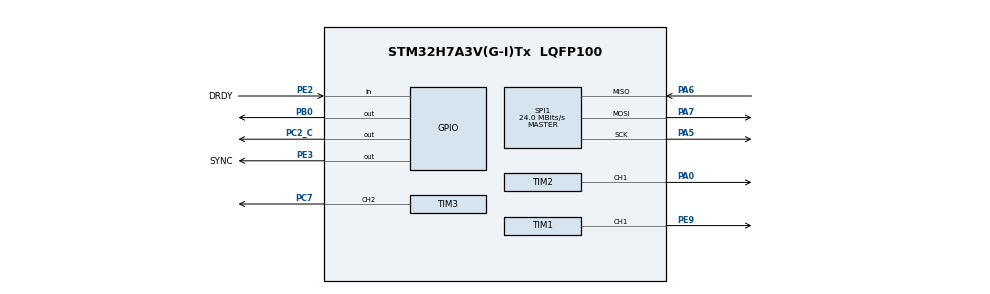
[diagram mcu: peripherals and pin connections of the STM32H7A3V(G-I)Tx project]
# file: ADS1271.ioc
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Mcu.Family=STM32H7
Mcu.Name=STM32H7A3V(G-I)Tx
Mcu.Package=LQFP100
NVIC.PriorityGroup=NVIC_PRIORITYGROUP_4
PA0.Signal=S_TIM2_CH1_ETR
PA5.Mode=Full_Duplex_Master
PA5.Signal=SPI1_SCK
PA6.Mode=Full_Duplex_Master
PA6.Signal=SPI1_MISO
PA7.Mode=Full_Duplex_Master
PA7.Signal=SPI1_MOSI
PB0.Signal=GPIO_Output
PB14.Signal=S_TIM12_CH1
PC2_C.Signal=GPIO_Output
PC7.Signal=S_TIM3_CH2
PE2.GPIO_Label=DRDY
PE2.Signal=GPIO_Input
PE3.GPIO_Label=SYNC
PE3.Signal=GPIO_Output
PE9.Signal=S_TIM1_CH1
ProjectManager.HeapSize=0x200
ProjectManager.StackSize=0x400
ProjectManager.TargetToolchain=STM32CubeIDE
RCC.ADCFreq_Value=96000000
RCC.APB1Freq_Value=140000000
RCC.APB2Freq_Value=140000000
RCC.APB3Freq_Value=140000000
RCC.APB4Freq_Value=140000000
RCC.CDPPRE=RCC_APB3_DIV2
RCC.CDPPRE1=RCC_APB1_DIV2
RCC.CDPPRE2=RCC_APB2_DIV2
RCC.CortexFreq_Value=280000000
RCC.DIVM1=16
RCC.DIVN1=140
RCC.DIVN2=144
RCC.DIVP2=3
RCC.HCLKFreq_Value=280000000
RCC.SPI123CLockSelection=RCC_SPI123CLKSOURCE_PLL2
RCC.SRDPPRE=RCC_APB4_DIV2
RCC.SYSCLKFreq_VALUE=280000000
RCC.SYSCLKSource=RCC_SYSCLKSOURCE_PLLCLK
RCC.USBFreq_Value=280000000
SH.S_TIM12_CH1.0=TIM12_CH1
SH.S_TIM1_CH1.0=TIM1_CH1,PWM Generation1 CH1
SH.S_TIM2_CH1_ETR.0=TIM2_CH1,PWM Generation1 CH1
SH.S_TIM3_CH2.0=TIM3_CH2,PWM Generation2 CH2
SPI1.BaudRatePrescaler=SPI_BAUDRATEPRESCALER_4
SPI1.CalculateBaudRate=24.0 MBits/s
SPI1.DataSize=SPI_DATASIZE_8BIT
SPI1.Direction=SPI_DIRECTION_2LINES
SPI1.Mode=SPI_MODE_MASTER
SPI1.VirtualType=VM_MASTER
TIM1.AutoReloadPreload=TIM_AUTORELOAD_PRELOAD_ENABLE
TIM1.Channel-PWM\ Generation1\ CH1=TIM_CHANNEL_1
TIM1.Period=10
TIM1.Prescaler=1-1
TIM2.AutoReloadPreload=TIM_AUTORELOAD_PRELOAD_ENABLE
TIM2.Channel-PWM\ Generation1\ CH1=TIM_CHANNEL_1
TIM2.Period=6
TIM2.Prescaler=2-1
TIM3.AutoReloadPreload=TIM_AUTORELOAD_PRELOAD_ENABLE
TIM3.Channel-PWM\ Generation2\ CH2=TIM_CHANNEL_2
TIM3.Period=6
TIM3.Prescaler=2-1
VP_TIM1_VS_ClockSourceINT.Mode=Internal
VP_TIM2_VS_ClockSourceINT.Mode=Internal
VP_TIM3_VS_ClockSourceINT.Mode=Internal
board=custom

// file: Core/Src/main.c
/* USER CODE BEGIN Header */
/**
  ******************************************************************************
  * @file           : main.c
  * @brief          : Main program body
  ******************************************************************************
  * @attention
  *
  * Copyright (c) 2024 STMicroelectronics.
  * All rights reserved.
  *
  * This software is licensed under terms that can be found in the LICENSE file
  * in the root directory of this software component.
  * If no LICENSE file comes with this software, it is provided AS-IS.
  *
  ******************************************************************************
  */
/* USER CODE END Header */
#include "main.h"

/* USER CODE BEGIN Includes */
#include "ads1271.h"
/* USER CODE END Includes */

SPI_HandleTypeDef hspi1;

TIM_HandleTypeDef htim1;
TIM_HandleTypeDef htim2;
TIM_HandleTypeDef htim3;

/* USER CODE BEGIN PV */
uint8_t tx_data[3] = {0x55};
uint8_t rx_data[3] = {0};
//int count = 0;

/* USER CODE END PV */

void SystemClock_Config(void);
static void MX_GPIO_Init(void);
static void MX_SPI1_Init(void);
static void MX_TIM1_Init(void);
static void MX_TIM3_Init(void);
static void MX_TIM2_Init(void);

int main(void)
{

  /* MCU Configuration--------------------------------------------------------*/

  /* Reset of all peripherals, Initializes the Flash interface and the Systick. */
  HAL_Init();

  /* Configure the system clock */
  SystemClock_Config();

  /* Initialize all configured peripherals */
  MX_GPIO_Init();
  MX_SPI1_Init();
  MX_TIM1_Init();
  MX_TIM3_Init();
  MX_TIM2_Init();
  /* USER CODE BEGIN 2 */
//  HAL_Delay(10000);

  HAL_GPIO_WritePin(GPIOB, GPIO_PIN_0, GPIO_PIN_SET);
TIM2->CCR1 = 3;
HAL_TIM_PWM_Start(&htim2, HAL_TIM_ACTIVE_CHANNEL_1);
//HAL_Delay(1);
//GPIOE->BSRR |= CS1_HIGH;
  /* USER CODE END 2 */

  /* Infinite loop */
  while (1)
  {

    /* USER CODE BEGIN 3 */

HAL_GPIO_WritePin(GPIOC, GPIO_PIN_2, GPIO_PIN_SET);
HAL_GPIO_WritePin(GPIOE, GPIO_PIN_3, GPIO_PIN_SET);
HAL_Delay(10);
HAL_GPIO_WritePin(GPIOC, GPIO_PIN_2, GPIO_PIN_RESET);
HAL_GPIO_WritePin(GPIOE, GPIO_PIN_3, GPIO_PIN_RESET);
HAL_Delay(10);

	 HAL_GPIO_WritePin(GPIOE, GPIO_PIN_3, GPIO_PIN_SET);

//	  SPI_rxtx(tx_data, rx_data, 3);
//	  for(int i = 0; i< 10000;i++);

  }
  /* USER CODE END 3 */
}

void SystemClock_Config(void)
{
  RCC_OscInitTypeDef RCC_OscInitStruct = {0};
  RCC_ClkInitTypeDef RCC_ClkInitStruct = {0};

  /*AXI clock gating */
  RCC->CKGAENR = 0xFFFFFFFF;

  /** Supply configuration update enable
  */
  HAL_PWREx_ConfigSupply(PWR_LDO_SUPPLY);

  /** Configure the main internal regulator output voltage
  */
  __HAL_PWR_VOLTAGESCALING_CONFIG(PWR_REGULATOR_VOLTAGE_SCALE0);

  while(!__HAL_PWR_GET_FLAG(PWR_FLAG_VOSRDY)) {}

  /** Initializes the RCC Oscillators according to the specified parameters
  * in the RCC_OscInitTypeDef structure.
  */
  RCC_OscInitStruct.OscillatorType = RCC_OSCILLATORTYPE_HSI;
  RCC_OscInitStruct.HSIState = RCC_HSI_DIV1;
  RCC_OscInitStruct.HSICalibrationValue = 64;
  RCC_OscInitStruct.PLL.PLLState = RCC_PLL_ON;
  RCC_OscInitStruct.PLL.PLLSource = RCC_PLLSOURCE_HSI;
  RCC_OscInitStruct.PLL.PLLM = 16;
  RCC_OscInitStruct.PLL.PLLN = 140;
  RCC_OscInitStruct.PLL.PLLP = 2;
  RCC_OscInitStruct.PLL.PLLQ = 2;
  RCC_OscInitStruct.PLL.PLLR = 2;
  RCC_OscInitStruct.PLL.PLLRGE = RCC_PLL1VCIRANGE_2;
  RCC_OscInitStruct.PLL.PLLVCOSEL = RCC_PLL1VCOWIDE;
  RCC_OscInitStruct.PLL.PLLFRACN = 0;
  if (HAL_RCC_OscConfig(&RCC_OscInitStruct) != HAL_OK)
  {
    Error_Handler();
  }

  /** Initializes the CPU, AHB and APB buses clocks
  */
  RCC_ClkInitStruct.ClockType = RCC_CLOCKTYPE_HCLK|RCC_CLOCKTYPE_SYSCLK
                              |RCC_CLOCKTYPE_PCLK1|RCC_CLOCKTYPE_PCLK2
                              |RCC_CLOCKTYPE_D3PCLK1|RCC_CLOCKTYPE_D1PCLK1;
  RCC_ClkInitStruct.SYSCLKSource = RCC_SYSCLKSOURCE_PLLCLK;
  RCC_ClkInitStruct.SYSCLKDivider = RCC_SYSCLK_DIV1;
  RCC_ClkInitStruct.AHBCLKDivider = RCC_HCLK_DIV1;
  RCC_ClkInitStruct.APB3CLKDivider = RCC_APB3_DIV2;
  RCC_ClkInitStruct.APB1CLKDivider = RCC_APB1_DIV2;
  RCC_ClkInitStruct.APB2CLKDivider = RCC_APB2_DIV2;
  RCC_ClkInitStruct.APB4CLKDivider = RCC_APB4_DIV2;

  if (HAL_RCC_ClockConfig(&RCC_ClkInitStruct, FLASH_LATENCY_6) != HAL_OK)
  {
    Error_Handler();
  }
}

static void MX_SPI1_Init(void)
{

  /* SPI1 parameter configuration*/
  hspi1.Instance = SPI1;
  hspi1.Init.Mode = SPI_MODE_MASTER;
  hspi1.Init.Direction = SPI_DIRECTION_2LINES;
  hspi1.Init.DataSize = SPI_DATASIZE_8BIT;
  hspi1.Init.CLKPolarity = SPI_POLARITY_LOW;
  hspi1.Init.CLKPhase = SPI_PHASE_1EDGE;
  hspi1.Init.NSS = SPI_NSS_SOFT;
  hspi1.Init.BaudRatePrescaler = SPI_BAUDRATEPRESCALER_4;
  hspi1.Init.FirstBit = SPI_FIRSTBIT_MSB;
  hspi1.Init.TIMode = SPI_TIMODE_DISABLE;
  hspi1.Init.CRCCalculation = SPI_CRCCALCULATION_DISABLE;
  hspi1.Init.CRCPolynomial = 0x0;
  hspi1.Init.NSSPMode = SPI_NSS_PULSE_ENABLE;
  hspi1.Init.NSSPolarity = SPI_NSS_POLARITY_LOW;
  hspi1.Init.FifoThreshold = SPI_FIFO_THRESHOLD_01DATA;
  hspi1.Init.TxCRCInitializationPattern = SPI_CRC_INITIALIZATION_ALL_ZERO_PATTERN;
  hspi1.Init.RxCRCInitializationPattern = SPI_CRC_INITIALIZATION_ALL_ZERO_PATTERN;
  hspi1.Init.MasterSSIdleness = SPI_MASTER_SS_IDLENESS_00CYCLE;
  hspi1.Init.MasterInterDataIdleness = SPI_MASTER_INTERDATA_IDLENESS_00CYCLE;
  hspi1.Init.MasterReceiverAutoSusp = SPI_MASTER_RX_AUTOSUSP_DISABLE;
  hspi1.Init.MasterKeepIOState = SPI_MASTER_KEEP_IO_STATE_DISABLE;
  hspi1.Init.IOSwap = SPI_IO_SWAP_DISABLE;
  if (HAL_SPI_Init(&hspi1) != HAL_OK)
  {
    Error_Handler();
  }

}

static void MX_TIM1_Init(void)
{

  TIM_ClockConfigTypeDef sClockSourceConfig = {0};
  TIM_MasterConfigTypeDef sMasterConfig = {0};
  TIM_OC_InitTypeDef sConfigOC = {0};
  TIM_BreakDeadTimeConfigTypeDef sBreakDeadTimeConfig = {0};

  htim1.Instance = TIM1;
  htim1.Init.Prescaler = 1-1;
  htim1.Init.CounterMode = TIM_COUNTERMODE_UP;
  htim1.Init.Period = 10;
  htim1.Init.ClockDivision = TIM_CLOCKDIVISION_DIV1;
  htim1.Init.RepetitionCounter = 0;
  htim1.Init.AutoReloadPreload = TIM_AUTORELOAD_PRELOAD_ENABLE;
  if (HAL_TIM_Base_Init(&htim1) != HAL_OK)
  {
    Error_Handler();
  }
  sClockSourceConfig.ClockSource = TIM_CLOCKSOURCE_INTERNAL;
  if (HAL_TIM_ConfigClockSource(&htim1, &sClockSourceConfig) != HAL_OK)
  {
    Error_Handler();
  }
  if (HAL_TIM_PWM_Init(&htim1) != HAL_OK)
  {
    Error_Handler();
  }
  sMasterConfig.MasterOutputTrigger = TIM_TRGO_RESET;
  sMasterConfig.MasterOutputTrigger2 = TIM_TRGO2_RESET;
  sMasterConfig.MasterSlaveMode = TIM_MASTERSLAVEMODE_DISABLE;
  if (HAL_TIMEx_MasterConfigSynchronization(&htim1, &sMasterConfig) != HAL_OK)
  {
    Error_Handler();
  }
  sConfigOC.OCMode = TIM_OCMODE_PWM1;
  sConfigOC.Pulse = 0;
  sConfigOC.OCPolarity = TIM_OCPOLARITY_HIGH;
  sConfigOC.OCNPolarity = TIM_OCNPOLARITY_HIGH;
  sConfigOC.OCFastMode = TIM_OCFAST_DISABLE;
  sConfigOC.OCIdleState = TIM_OCIDLESTATE_RESET;
  sConfigOC.OCNIdleState = TIM_OCNIDLESTATE_RESET;
  if (HAL_TIM_PWM_ConfigChannel(&htim1, &sConfigOC, TIM_CHANNEL_1) != HAL_OK)
  {
    Error_Handler();
  }
  sBreakDeadTimeConfig.OffStateRunMode = TIM_OSSR_DISABLE;
  sBreakDeadTimeConfig.OffStateIDLEMode = TIM_OSSI_DISABLE;
  sBreakDeadTimeConfig.LockLevel = TIM_LOCKLEVEL_OFF;
  sBreakDeadTimeConfig.DeadTime = 0;
  sBreakDeadTimeConfig.BreakState = TIM_BREAK_DISABLE;
  sBreakDeadTimeConfig.BreakPolarity = TIM_BREAKPOLARITY_HIGH;
  sBreakDeadTimeConfig.BreakFilter = 0;
  sBreakDeadTimeConfig.Break2State = TIM_BREAK2_DISABLE;
  sBreakDeadTimeConfig.Break2Polarity = TIM_BREAK2POLARITY_HIGH;
  sBreakDeadTimeConfig.Break2Filter = 0;
  sBreakDeadTimeConfig.AutomaticOutput = TIM_AUTOMATICOUTPUT_DISABLE;
  if (HAL_TIMEx_ConfigBreakDeadTime(&htim1, &sBreakDeadTimeConfig) != HAL_OK)
  {
    Error_Handler();
  }
  HAL_TIM_MspPostInit(&htim1);

}

static void MX_TIM2_Init(void)
{

  TIM_ClockConfigTypeDef sClockSourceConfig = {0};
  TIM_MasterConfigTypeDef sMasterConfig = {0};
  TIM_OC_InitTypeDef sConfigOC = {0};

  htim2.Instance = TIM2;
  htim2.Init.Prescaler = 2-1;
  htim2.Init.CounterMode = TIM_COUNTERMODE_UP;
  htim2.Init.Period = 6;
  htim2.Init.ClockDivision = TIM_CLOCKDIVISION_DIV1;
  htim2.Init.AutoReloadPreload = TIM_AUTORELOAD_PRELOAD_ENABLE;
  if (HAL_TIM_Base_Init(&htim2) != HAL_OK)
  {
    Error_Handler();
  }
  sClockSourceConfig.ClockSource = TIM_CLOCKSOURCE_INTERNAL;
  if (HAL_TIM_ConfigClockSource(&htim2, &sClockSourceConfig) != HAL_OK)
  {
    Error_Handler();
  }
  if (HAL_TIM_PWM_Init(&htim2) != HAL_OK)
  {
    Error_Handler();
  }
  sMasterConfig.MasterOutputTrigger = TIM_TRGO_RESET;
  sMasterConfig.MasterSlaveMode = TIM_MASTERSLAVEMODE_DISABLE;
  if (HAL_TIMEx_MasterConfigSynchronization(&htim2, &sMasterConfig) != HAL_OK)
  {
    Error_Handler();
  }
  sConfigOC.OCMode = TIM_OCMODE_PWM1;
  sConfigOC.Pulse = 0;
  sConfigOC.OCPolarity = TIM_OCPOLARITY_HIGH;
  sConfigOC.OCFastMode = TIM_OCFAST_DISABLE;
  if (HAL_TIM_PWM_ConfigChannel(&htim2, &sConfigOC, TIM_CHANNEL_1) != HAL_OK)
  {
    Error_Handler();
  }
  HAL_TIM_MspPostInit(&htim2);

}

static void MX_TIM3_Init(void)
{

  TIM_ClockConfigTypeDef sClockSourceConfig = {0};
  TIM_MasterConfigTypeDef sMasterConfig = {0};
  TIM_OC_InitTypeDef sConfigOC = {0};

  htim3.Instance = TIM3;
  htim3.Init.Prescaler = 2-1;
  htim3.Init.CounterMode = TIM_COUNTERMODE_UP;
  htim3.Init.Period = 6;
  htim3.Init.ClockDivision = TIM_CLOCKDIVISION_DIV1;
  htim3.Init.AutoReloadPreload = TIM_AUTORELOAD_PRELOAD_ENABLE;
  if (HAL_TIM_Base_Init(&htim3) != HAL_OK)
  {
    Error_Handler();
  }
  sClockSourceConfig.ClockSource = TIM_CLOCKSOURCE_INTERNAL;
  if (HAL_TIM_ConfigClockSource(&htim3, &sClockSourceConfig) != HAL_OK)
  {
    Error_Handler();
  }
  if (HAL_TIM_PWM_Init(&htim3) != HAL_OK)
  {
    Error_Handler();
  }
  sMasterConfig.MasterOutputTrigger = TIM_TRGO_RESET;
  sMasterConfig.MasterSlaveMode = TIM_MASTERSLAVEMODE_DISABLE;
  if (HAL_TIMEx_MasterConfigSynchronization(&htim3, &sMasterConfig) != HAL_OK)
  {
    Error_Handler();
  }
  sConfigOC.OCMode = TIM_OCMODE_PWM1;
  sConfigOC.Pulse = 0;
  sConfigOC.OCPolarity = TIM_OCPOLARITY_HIGH;
  sConfigOC.OCFastMode = TIM_OCFAST_DISABLE;
  if (HAL_TIM_PWM_ConfigChannel(&htim3, &sConfigOC, TIM_CHANNEL_2) != HAL_OK)
  {
    Error_Handler();
  }
  HAL_TIM_MspPostInit(&htim3);

}

static void MX_GPIO_Init(void)
{
  GPIO_InitTypeDef GPIO_InitStruct = {0};

  /* GPIO Ports Clock Enable */
  __HAL_RCC_GPIOE_CLK_ENABLE();
  __HAL_RCC_GPIOC_CLK_ENABLE();
  __HAL_RCC_GPIOA_CLK_ENABLE();
  __HAL_RCC_GPIOB_CLK_ENABLE();

  /*Configure GPIO pin Output Level */
  HAL_GPIO_WritePin(SYNC_GPIO_Port, SYNC_Pin, GPIO_PIN_RESET);

  /*Configure GPIO pin Output Level */
  HAL_GPIO_WritePin(GPIOC, GPIO_PIN_2, GPIO_PIN_RESET);

  /*Configure GPIO pin Output Level */
  HAL_GPIO_WritePin(GPIOB, GPIO_PIN_0, GPIO_PIN_RESET);

  /*Configure GPIO pin : DRDY_Pin */
  GPIO_InitStruct.Pin = DRDY_Pin;
  GPIO_InitStruct.Mode = GPIO_MODE_INPUT;
  GPIO_InitStruct.Pull = GPIO_NOPULL;
  HAL_GPIO_Init(DRDY_GPIO_Port, &GPIO_InitStruct);

  /*Configure GPIO pin : SYNC_Pin */
  GPIO_InitStruct.Pin = SYNC_Pin;
  GPIO_InitStruct.Mode = GPIO_MODE_OUTPUT_PP;
  GPIO_InitStruct.Pull = GPIO_NOPULL;
  GPIO_InitStruct.Speed = GPIO_SPEED_FREQ_LOW;
  HAL_GPIO_Init(SYNC_GPIO_Port, &GPIO_InitStruct);

  /*Configure GPIO pin : PC2 */
  GPIO_InitStruct.Pin = GPIO_PIN_2;
  GPIO_InitStruct.Mode = GPIO_MODE_OUTPUT_PP;
  GPIO_InitStruct.Pull = GPIO_NOPULL;
  GPIO_InitStruct.Speed = GPIO_SPEED_FREQ_LOW;
  HAL_GPIO_Init(GPIOC, &GPIO_InitStruct);

  /*Configure GPIO pin : PB0 */
  GPIO_InitStruct.Pin = GPIO_PIN_0;
  GPIO_InitStruct.Mode = GPIO_MODE_OUTPUT_PP;
  GPIO_InitStruct.Pull = GPIO_NOPULL;
  GPIO_InitStruct.Speed = GPIO_SPEED_FREQ_LOW;
  HAL_GPIO_Init(GPIOB, &GPIO_InitStruct);

  /*Configure GPIO pin : PB14 */
  GPIO_InitStruct.Pin = GPIO_PIN_14;
  GPIO_InitStruct.Mode = GPIO_MODE_AF_PP;
  GPIO_InitStruct.Pull = GPIO_NOPULL;
  GPIO_InitStruct.Speed = GPIO_SPEED_FREQ_LOW;
  GPIO_InitStruct.Alternate = GPIO_AF2_TIM12;
  HAL_GPIO_Init(GPIOB, &GPIO_InitStruct);

}

void Error_Handler(void)
{
  __disable_irq();
  while (1)
  {
  }
}
